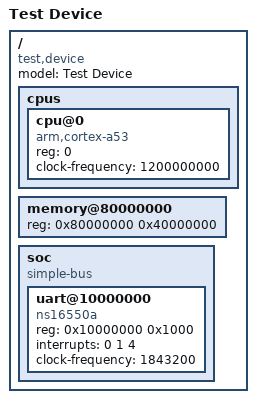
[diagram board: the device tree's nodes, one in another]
/dts-v1/;

/ {
    compatible = "test,device";
    model = "Test Device";
    #address-cells = <1>;
    #size-cells = <1>;

    cpus {
        #address-cells = <1>;
        #size-cells = <0>;

        cpu@0 {
            device_type = "cpu";
            compatible = "arm,cortex-a53";
            reg = <0>;
            clock-frequency = <1200000000>;
        };
    };

    memory@80000000 {
        device_type = "memory";
        reg = <0x80000000 0x40000000>;
    };

    soc {
        compatible = "simple-bus";
        #address-cells = <1>;
        #size-cells = <1>;
        ranges;

        uart@10000000 {
            compatible = "ns16550a";
            reg = <0x10000000 0x1000>;
            interrupts = <0 1 4>;
            clock-frequency = <1843200>;
        };
    };
};
